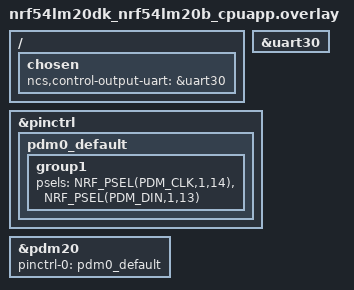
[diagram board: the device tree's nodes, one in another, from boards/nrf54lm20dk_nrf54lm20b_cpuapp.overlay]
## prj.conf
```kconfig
#
# Copyright (c) 2026 Nordic Semiconductor
#
# SPDX-License-Identifier: LicenseRef-Nordic-5-Clause
#

# nRF Edge AI
CONFIG_NRF_EDGEAI=y

# nRF Edge AI dependencies
CONFIG_NRF_AXON=y
CONFIG_NEWLIB_LIBC=y
CONFIG_FPU=y

# Size of interlayer buffer to fit model
CONFIG_NRF_AXON_INTERLAYER_BUFFER_SIZE=6700

# Size of psum buffer to fit model
CONFIG_NRF_AXON_PSUM_BUFFER_SIZE=0

# Peripherals
CONFIG_GPIO=y
CONFIG_SERIAL=y
CONFIG_UART_ASYNC_API=y
CONFIG_NRFX_PDM=y

# Enable logging and assert
CONFIG_LOG=y
CONFIG_CONSOLE=y
CONFIG_ASSERT=y

CONFIG_MAIN_STACK_SIZE=4096

CONFIG_AUDIO=y
CONFIG_AUDIO_DMIC=y
CONFIG_AUDIO_DMIC_NRFX_PDM=y
```

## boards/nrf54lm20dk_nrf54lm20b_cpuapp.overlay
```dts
/*
 * Copyright (c) 2026 Nordic Semiconductor ASA
 *
 * SPDX-License-Identifier: Apache-2.0
 */

#include "nrf54lm20dk_nrf54lm20_common.dtsi"

/ {
    chosen {
        ncs,control-output-uart = &uart30;
    };
};

&uart30 {
	status = "okay";
};

&pinctrl {
    pdm0_default: pdm0_default {
        group1 {
	    // set the pin configuration for PDM_CLK and PDM_DIN
	    psels = <NRF_PSEL(PDM_CLK,1,14)>, <NRF_PSEL(PDM_DIN,1,13)>;
	};
    };
};

&pdm20 {
    status = "okay"; // turns on PDM driver
    pinctrl-0 = <&pdm0_default>;
    pinctrl-names = "default";
};
```

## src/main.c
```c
/*
 * Copyright (c) 2026 Nordic Semiconductor ASA
 *
 * SPDX-License-Identifier: LicenseRef-Nordic-5-Clause
 */

#include <errno.h>
#include <stdbool.h>

#include <zephyr/logging/log.h>

#include "control_output.h"
#include "dmic.h"
#include "leds.h"
#include "wakeword.h"

LOG_MODULE_REGISTER(main);

int main(void)
{
	int err;

	err = dmic_init();
	if (err) {
		return err;
	}

	err = leds_init();
	if (err) {
		return err;
	}

	err = control_output_init();
	if (err) {
		return err;
	}

	err = ww_init();
	if (err) {
		return err;
	}

	LOG_INF("Initialization completed");

	err = dmic_start();
	if (err < 0) {
		LOG_ERR("Failed to start audio capture (err %d)", err);
		return err;
	}

	print_control_output((struct control_message){CONTROL_MESSAGE_WAITING_WW});

	while (true) {
		void *audio_buffer;
		size_t audio_buffer_size;
		bool ww_detected;

		const int32_t read_timeout = 100;

		err = dmic_read_buffer(&audio_buffer, &audio_buffer_size, read_timeout);
		if (err < 0) {
			LOG_ERR("Failed to read audio (err %d)", err);
			return err;
		}

		err = ww_process(audio_buffer, audio_buffer_size / DMIC_SAMPLE_BYTES, &ww_detected);
		if (err == -EBUSY) {
			continue;
		} else if (err < 0) {
			LOG_ERR("Wakeword detection failed (err %d)", err);
			return err;
		}

		if (ww_detected) {
			LOG_INF("Wake word detected");
			leds_blink_led0();
			print_control_output((struct control_message){CONTROL_MESSAGE_WW_DETECTED});
		}
	}

	return 0;
}
```

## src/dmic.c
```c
/*
 * Copyright (c) 2026 Nordic Semiconductor ASA
 *
 * SPDX-License-Identifier: LicenseRef-Nordic-5-Clause
 */

#include <errno.h>

#include <zephyr/kernel.h>
#include <zephyr/device.h>
#include <zephyr/logging/log.h>
#include <zephyr/audio/dmic.h>

#include "dmic.h"

LOG_MODULE_REGISTER(dmic);

#define AUDIO_BLOCK_SIZE \
    ((DMIC_PCM_RATE * SAMPLES_BLOCK_LENGTH_MS / 1000) * DMIC_SAMPLE_BYTES)
#define BLOCK_COUNT 8

/* Devicetree node: your overlay labels this pdm20 node as dmic_dev */
static const struct device *const pdm_dev = DEVICE_DT_GET(DT_NODELABEL(dmic_dev));

K_MEM_SLAB_DEFINE_STATIC(app_mem_slab, AUDIO_BLOCK_SIZE, BLOCK_COUNT, 4);

static struct pcm_stream_cfg stream_cfg;
static struct dmic_cfg cfg;

int dmic_init(void)
{
    int ret;

    if (!device_is_ready(pdm_dev)) {
        LOG_ERR("%s is not ready", pdm_dev->name);
        return -ENODEV;
    }

    stream_cfg.pcm_rate = DMIC_PCM_RATE;
    stream_cfg.pcm_width = 16;
    stream_cfg.block_size = AUDIO_BLOCK_SIZE;
    stream_cfg.mem_slab = &app_mem_slab;

    cfg.io.min_pdm_clk_freq = 1000000;
    cfg.io.max_pdm_clk_freq = 3500000;
    cfg.io.min_pdm_clk_dc = 40;
    cfg.io.max_pdm_clk_dc = 60;

    cfg.streams = &stream_cfg;

    cfg.channel.req_num_streams = 1;
    cfg.channel.req_num_chan = 1;
    cfg.channel.req_chan_map_lo =
        dmic_build_channel_map(0, 0, PDM_CHAN_LEFT);
    cfg.channel.req_chan_map_hi = 0;

    ret = dmic_configure(pdm_dev, &cfg);
    if (ret < 0) {
        LOG_ERR("dmic_configure failed: %d", ret);
        return ret;
    }

    LOG_INF("PDM DMIC initialized at %d Hz", DMIC_PCM_RATE);
    return 0;
}

int dmic_start(void)
{
    int ret = dmic_trigger(pdm_dev, DMIC_TRIGGER_START);

    if (ret < 0) {
        LOG_ERR("DMIC start failed: %d", ret);
        return ret;
    }

    LOG_INF("PDM DMIC capture started");
    return 0;
}

int dmic_read_buffer(void **buffer, size_t *buffer_size, int32_t timeout_ms)
{
    int ret;
    size_t size;
    void *mem_block;

    ret = dmic_read(pdm_dev, 0, &mem_block, &size, timeout_ms);
    if (ret < 0) {
        LOG_ERR("dmic_read failed: %d", ret);
        return ret;
    }

    *buffer = mem_block;
    *buffer_size = size;

    return 0;
}

void free_dmic_buffer(void *buffer)
{
    k_mem_slab_free(&app_mem_slab, buffer);
}
```

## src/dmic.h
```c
/*
 * Copyright (c) 2026 Nordic Semiconductor ASA
 *
 * SPDX-License-Identifier: LicenseRef-Nordic-5-Clause
 */

/**
 * @defgroup dmic Audio input control functions
 * @{
 * @ingroup ww_kws
 */

#ifndef __DMIC_H__
#define __DMIC_H__

#include <stddef.h>
#include <stdint.h>

#ifdef __cplusplus
extern "C" {
#endif /* __cplusplus */

#define DMIC_SAMPLE_BYTES (2)
#define DMIC_PCM_RATE (16000)
#define SAMPLES_BLOCK_LENGTH_MS (10)

int dmic_init(void);
int dmic_start(void);
int dmic_read_buffer(void **buffer, size_t *buffer_size, int32_t timeout_ms);
void free_dmic_buffer(void *buffer);

#ifdef __cplusplus
}
#endif /* __cplusplus */

#endif /* __DMIC_H__ */

/**
 * @}
 */
```
